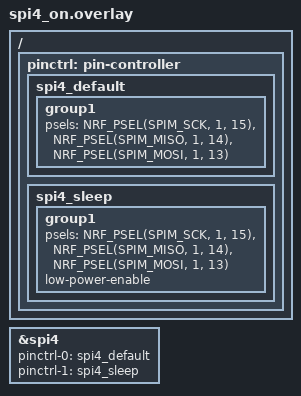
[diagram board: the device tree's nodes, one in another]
/ {
	pinctrl: pin-controller {
		spi4_default: spi4_default {
			group1 {
				psels = <NRF_PSEL(SPIM_SCK, 1, 15)>,
						<NRF_PSEL(SPIM_MISO, 1, 14)>,
						<NRF_PSEL(SPIM_MOSI, 1, 13)>;
			};
		};
		spi4_sleep: spi4_sleep {
			group1 {
				psels = <NRF_PSEL(SPIM_SCK, 1, 15)>,
					<NRF_PSEL(SPIM_MISO, 1, 14)>,
					<NRF_PSEL(SPIM_MOSI, 1, 13)>;
				low-power-enable;
			};
		};
	};
};

&spi4 {
	status = "okay";
	pinctrl-0 = <&spi4_default>;
	pinctrl-1 = <&spi4_sleep>;
};


